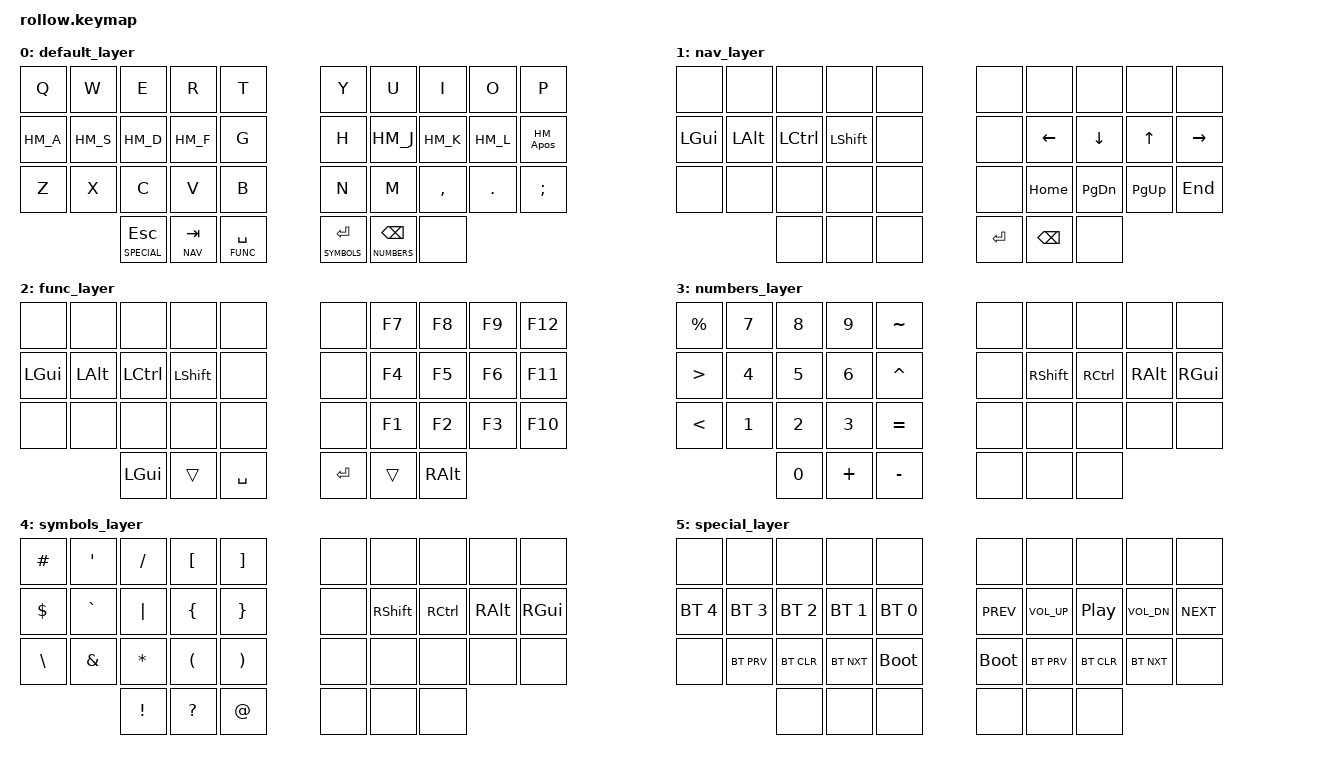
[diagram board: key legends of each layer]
#include <behaviors.dtsi>
#include <dt-bindings/zmk/keys.h>
#include <dt-bindings/zmk/bt.h>

#include "definitions.dtsi"
#include "homerow.dtsi"
#include "combos.dtsi"

/* 
*
*#include "unicode.dtsi"
*#include "tapdances.dtsi"
*
*/
/ {
        chosen {
                zmk,matrix_transform = &five_column_transform;
        };

        keymap {
                compatible = "zmk,keymap";

                default_layer {
/* Default
 *   Encoder Left: Up <-> Down
 *   Encoder Right: Left <-> Right
 */
                        bindings = <
   &kp Q &kp W &kp E &kp R &kp T   &kp Y &kp U  &kp I     &kp O   &kp P
   HM_A  HM_S  HM_D  HM_F  &kp G     &kp H HM_J   HM_K      HM_L    HM_Apos
   &kp Z &kp X &kp C &kp V &kp B   &kp N &kp M  &kp COMMA &kp DOT &kp SEMI
      &lt SPECIAL ESC     &lt  NAV TAB   &lt FUNC SPACE   &lt SYMBOLS ENTER     &lt NUMBERS BSPC &none
                        >;
                        sensor-bindings = <&inc_dec_kp DOWN UP &inc_dec_kp RIGHT LEFT>;
                };
                        nav_layer {
/* Navi
 *   Encoder Left: switch virtual desktop 
 *   Encoder Right: switch virtual desktop
 */
                        bindings = <
       &none       &none       &none      &none       &none            &none   &none   &none &none    &none 
    &kp LGUI &kp LALT &kp LCTRL &kp LSHFT &none     &none &kp LEFT &kp DOWN &kp UP &kp RIGHT 
     &none       &none       &none       &none       &none            &none &kp HOME  &kp PG_DN &kp PG_UP    &kp END 
                &none     &none       &none         &kp ENTER     &kp BSPC &none
                            >;

                            sensor-bindings = <&inc_dec_kp LG(LA(LEFT)) LG(LA(RIGHT)) &inc_dec_kp LG(LC(LEFT)) LG(LC(RIGHT))>;
                };
                        func_layer {
/* Func
 *
 *   Encoder Left: -
 *   Encoder Right: VOL_UP <-> VOL_D
 */
                        bindings = <
     &none  &none  &none   &none   &none            &none &kp        F7 &kp        F8 &kp        F9 &kp     F12 
     &kp LGUI &kp LALT &kp LCTRL &kp LSHFT &none     &none &kp F4        &kp        F5 &kp        F6 &kp        F11 
      &none  &none  &none   &none   &none      &none  &kp        F1 &kp    F2 &kp   F3 &kp    F10 
                                   &kp LGUI &trans &kp SPACE   &kp RET &trans &kp RALT
                        >;
   
                        sensor-bindings = <&inc_dec_kp C_VOL_UP C_VOL_DN &inc_dec_kp PG_UP PG_DN>;
                };
                        numbers_layer {
/* numbers
 *
 *   Encoder Left: -
 *   Encoder Right: VOL_UP <-> VOL_D
 */
                        bindings = <
     &kp PRCNT &kp N7 &kp N8 &kp N9 &kp TILDE       &none  &none  &none  &none   &none   
     &kp GT &kp N4 &kp N5 &kp N6 &kp CARET           &none &kp RSHFT &kp RCTRL &kp  RALT &kp  RGUI 
     &kp LT &kp N1 &kp N2 &kp N3 &kp EQUAL           &none  &none  &none  &none   &none   
                                   &kp N0 &kp PLUS &kp MINUS  &none &none &none
                        >;
   
                        sensor-bindings = <&inc_dec_kp C_VOL_UP C_VOL_DN &inc_dec_kp C_PREV C_NEXT>;
                };
                symbols_layer {
/* symbols
 *
 *   Encoder Left: -
 *   Encoder Right: VOL_UP <-> VOL_D
 */
                        bindings = <
     &kp HASH &kp APOS &kp FSLH &kp LBKT &kp RBKT       &none  &none  &none  &none   &none   
     &kp DLLR &kp GRAVE &kp PIPE &kp LBRC &kp RBRC         &none &kp RSHFT &kp RCTRL &kp  RALT &kp  RGUI 
     &kp BSLH &kp AMPS &kp ASTRK &kp LPAR &kp RPAR           &none  &none  &none  &none   &none   
                                   &kp EXCL &kp QMARK &kp AT  &none &none &none
                        >;
   
                        sensor-bindings = <&inc_dec_kp C_VOL_UP C_VOL_DN &inc_dec_kp C_PREV C_NEXT>;
                };
                        special_layer {
/* special
 *
 *   Encoder Left: -
 *   Encoder Right: VOL_UP <-> VOL_D
 */
                        bindings = <
      &none  &none  &none   &none   &none       &none  &none  &none  &none   &none   
     &bt BT_SEL 4 &bt BT_SEL 3 &bt BT_SEL 2 &bt BT_SEL 1 &bt BT_SEL 0        &kp C_PREV &kp C_VOL_UP  &kp C_PP &kp C_VOL_DN   &kp C_NEXT   
    &none &bt   BT_PRV &bt   BT_CLR &bt   BT_NXT &bootloader          &bootloader  &bt   BT_PRV &bt   BT_CLR &bt   BT_NXT &none   
                                   &none &none &none  &none &none &none
                        >;
   
                        sensor-bindings = <&inc_dec_kp C_VOL_UP C_VOL_DN &inc_dec_kp C_PREV C_NEXT>;
                };        

        
        
        };
};
